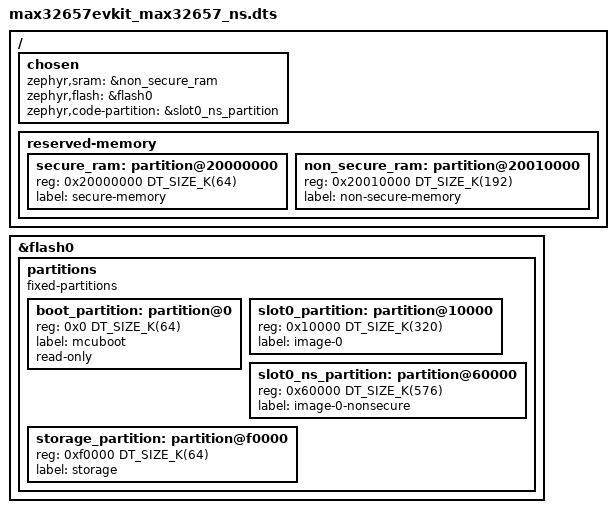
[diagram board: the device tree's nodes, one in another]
/*
 * Copyright (c) 2024-2025 Analog Devices, Inc.
 *
 * SPDX-License-Identifier: Apache-2.0
 */

/dts-v1/;

#include <adi/max32/max32657_ns.dtsi>
#include "max32657evkit_max32657_common.dtsi"

/ {
	chosen {
		zephyr,sram = &non_secure_ram;
		zephyr,flash = &flash0;
		zephyr,code-partition = &slot0_ns_partition;
	};

	reserved-memory {
		ranges;
		#address-cells = <1>;
		#size-cells = <1>;

		/* RAM split used by TFM */
		secure_ram: partition@20000000 {
			reg = <0x20000000 DT_SIZE_K(64)>;
			label = "secure-memory";
		};

		non_secure_ram: partition@20010000 {
			reg = <0x20010000 DT_SIZE_K(192)>;
			label = "non-secure-memory";
		};
	};
};

&flash0 {
	partitions {
		compatible = "fixed-partitions";
		#address-cells = <1>;
		#size-cells = <1>;

		boot_partition: partition@0 {
			reg = <0x0 DT_SIZE_K(64)>;
			label = "mcuboot";
			read-only;
		};

		slot0_partition: partition@10000 {
			reg = <0x10000 DT_SIZE_K(320)>;
			label = "image-0";
		};

		slot0_ns_partition: partition@60000 {
			reg = <0x60000 DT_SIZE_K(576)>;
			label = "image-0-nonsecure";
		};

		/*
		 * slot1_partition: partition@f0000 {
		 *  label = "image-1";
		 *	reg = <0xf0000 DT_SIZE_K(0)>;
		 * };
		 * slot1_ns_partition: partition@f0000 {
		 *	label = "image-1-nonsecure";
		 *	reg = <0xf0000 DT_SIZE_K(0)>;
		 * };
		 */

		storage_partition: partition@f0000 {
			reg = <0xf0000 DT_SIZE_K(64)>;
			label = "storage";
		};
	};
};
